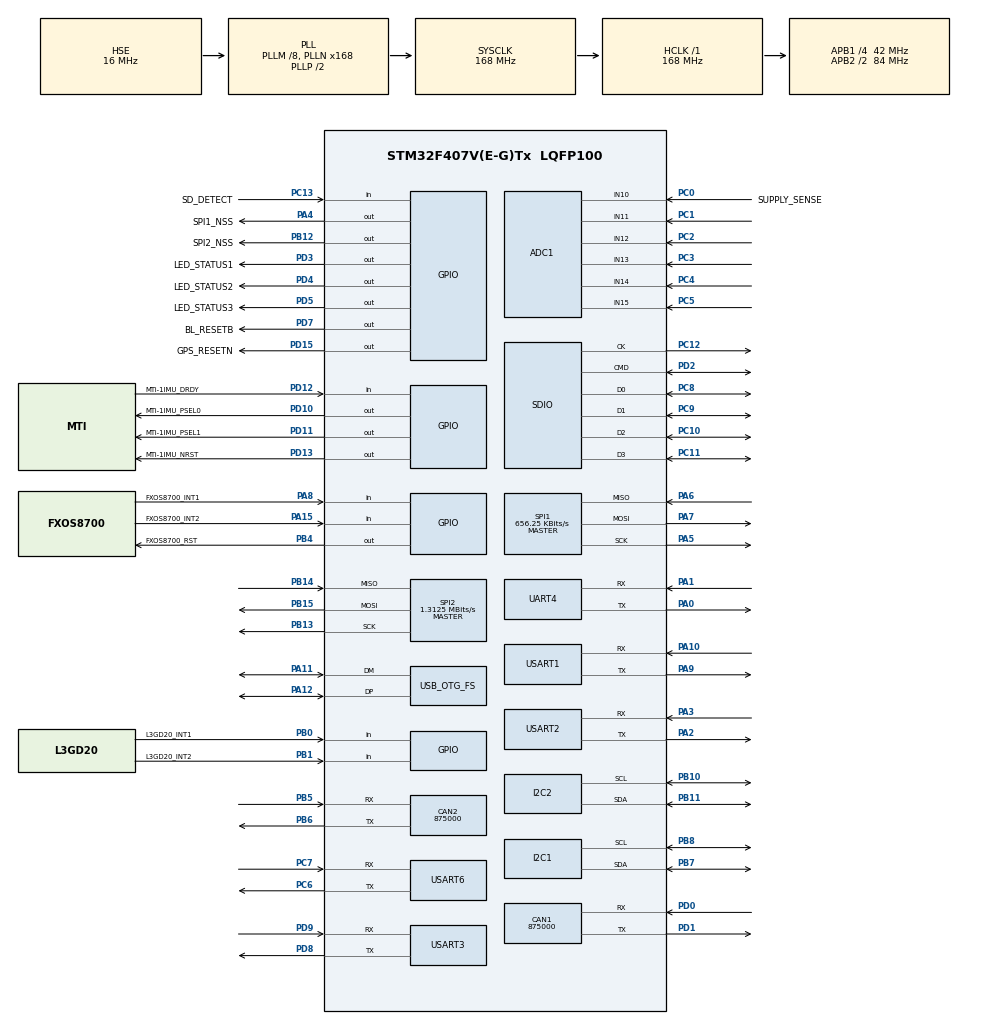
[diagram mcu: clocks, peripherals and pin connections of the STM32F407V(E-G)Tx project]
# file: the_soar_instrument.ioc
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ADC1.Channel-0\#ChannelRegularConversion=ADC_CHANNEL_10
ADC1.NbrOfConversionFlag=1
ADC1.Rank-0\#ChannelRegularConversion=1
ADC1.SamplingTime-0\#ChannelRegularConversion=ADC_SAMPLETIME_3CYCLES
ADC1.master=1
CAN1.CalculateBaudRate=875000
CAN1.CalculateTimeBit=1142.85
CAN1.CalculateTimeQuantum=380.95238095238096
CAN2.CalculateBaudRate=875000
CAN2.CalculateTimeBit=1142.85
CAN2.CalculateTimeQuantum=380.95238095238096
Dma.Request0=SDIO_RX
Dma.Request1=SDIO_TX
Dma.Request2=SPI2_RX
Dma.Request3=SPI2_TX
Dma.Request4=SPI1_RX
Dma.Request5=SPI1_TX
Dma.SDIO_RX.0.Direction=DMA_PERIPH_TO_MEMORY
Dma.SDIO_RX.0.FIFOMode=DMA_FIFOMODE_ENABLE
Dma.SDIO_RX.0.FIFOThreshold=DMA_FIFO_THRESHOLD_FULL
Dma.SDIO_RX.0.Instance=DMA2_Stream3
Dma.SDIO_RX.0.MemBurst=DMA_MBURST_INC4
Dma.SDIO_RX.0.MemDataAlignment=DMA_MDATAALIGN_WORD
Dma.SDIO_RX.0.MemInc=DMA_MINC_ENABLE
Dma.SDIO_RX.0.Mode=DMA_PFCTRL
Dma.SDIO_RX.0.PeriphBurst=DMA_PBURST_INC4
Dma.SDIO_RX.0.PeriphDataAlignment=DMA_PDATAALIGN_WORD
Dma.SDIO_RX.0.PeriphInc=DMA_PINC_DISABLE
Dma.SDIO_RX.0.Priority=DMA_PRIORITY_LOW
Dma.SDIO_TX.1.Direction=DMA_MEMORY_TO_PERIPH
Dma.SDIO_TX.1.FIFOMode=DMA_FIFOMODE_ENABLE
Dma.SDIO_TX.1.FIFOThreshold=DMA_FIFO_THRESHOLD_FULL
Dma.SDIO_TX.1.Instance=DMA2_Stream6
Dma.SDIO_TX.1.MemBurst=DMA_MBURST_INC4
Dma.SDIO_TX.1.MemDataAlignment=DMA_MDATAALIGN_WORD
Dma.SDIO_TX.1.MemInc=DMA_MINC_ENABLE
Dma.SDIO_TX.1.Mode=DMA_PFCTRL
Dma.SDIO_TX.1.PeriphBurst=DMA_PBURST_INC4
Dma.SDIO_TX.1.PeriphDataAlignment=DMA_PDATAALIGN_WORD
Dma.SDIO_TX.1.PeriphInc=DMA_PINC_DISABLE
Dma.SDIO_TX.1.Priority=DMA_PRIORITY_LOW
Dma.SPI1_RX.4.Direction=DMA_PERIPH_TO_MEMORY
Dma.SPI1_RX.4.FIFOMode=DMA_FIFOMODE_DISABLE
Dma.SPI1_RX.4.Instance=DMA2_Stream0
Dma.SPI1_RX.4.MemDataAlignment=DMA_MDATAALIGN_BYTE
Dma.SPI1_RX.4.MemInc=DMA_MINC_ENABLE
Dma.SPI1_RX.4.Mode=DMA_NORMAL
Dma.SPI1_RX.4.PeriphDataAlignment=DMA_PDATAALIGN_BYTE
Dma.SPI1_RX.4.PeriphInc=DMA_PINC_DISABLE
Dma.SPI1_RX.4.Priority=DMA_PRIORITY_LOW
Dma.SPI1_TX.5.Direction=DMA_MEMORY_TO_PERIPH
Dma.SPI1_TX.5.FIFOMode=DMA_FIFOMODE_DISABLE
Dma.SPI1_TX.5.Instance=DMA2_Stream5
Dma.SPI1_TX.5.MemDataAlignment=DMA_MDATAALIGN_BYTE
Dma.SPI1_TX.5.MemInc=DMA_MINC_ENABLE
Dma.SPI1_TX.5.Mode=DMA_NORMAL
Dma.SPI1_TX.5.PeriphDataAlignment=DMA_PDATAALIGN_BYTE
Dma.SPI1_TX.5.PeriphInc=DMA_PINC_DISABLE
Dma.SPI1_TX.5.Priority=DMA_PRIORITY_LOW
Dma.SPI2_RX.2.Direction=DMA_PERIPH_TO_MEMORY
Dma.SPI2_RX.2.FIFOMode=DMA_FIFOMODE_DISABLE
Dma.SPI2_RX.2.Instance=DMA1_Stream3
Dma.SPI2_RX.2.MemDataAlignment=DMA_MDATAALIGN_BYTE
Dma.SPI2_RX.2.MemInc=DMA_MINC_ENABLE
Dma.SPI2_RX.2.Mode=DMA_NORMAL
Dma.SPI2_RX.2.PeriphDataAlignment=DMA_PDATAALIGN_BYTE
Dma.SPI2_RX.2.PeriphInc=DMA_PINC_DISABLE
Dma.SPI2_RX.2.Priority=DMA_PRIORITY_LOW
Dma.SPI2_TX.3.Direction=DMA_MEMORY_TO_PERIPH
Dma.SPI2_TX.3.FIFOMode=DMA_FIFOMODE_DISABLE
Dma.SPI2_TX.3.Instance=DMA1_Stream4
Dma.SPI2_TX.3.MemDataAlignment=DMA_MDATAALIGN_BYTE
Dma.SPI2_TX.3.MemInc=DMA_MINC_ENABLE
Dma.SPI2_TX.3.Mode=DMA_NORMAL
Dma.SPI2_TX.3.PeriphDataAlignment=DMA_PDATAALIGN_BYTE
Dma.SPI2_TX.3.PeriphInc=DMA_PINC_DISABLE
Dma.SPI2_TX.3.Priority=DMA_PRIORITY_LOW
FATFS.BSP.number=1
FATFS0.BSP.STBoard=false
FATFS0.BSP.api=Unknown
FATFS0.BSP.i2caddr=0
FATFS0.BSP.instance=PC13-ANTI_TAMP
FATFS0.BSP.ip=GPIO
FATFS0.BSP.mode=Input
FATFS0.BSP.name=Detect_SDIO
FATFS0.BSP.solution=PC13-ANTI_TAMP
FREERTOS.INCLUDE_vTaskDelayUntil=1
FREERTOS.Tasks01=defaultTask,0,512,StartDefaultTask,Default,NULL,Dynamic,NULL,NULL
I2C1.I2C_Mode=I2C_Fast
I2C2.I2C_Mode=I2C_Fast
Mcu.Family=STM32F4
Mcu.Name=STM32F407V(E-G)Tx
Mcu.Package=LQFP100
NVIC.DMA1_Stream3_IRQn=true\:5\:0\:false\:false\:true\:true\:false\:true
NVIC.DMA1_Stream4_IRQn=true\:5\:0\:false\:false\:true\:true\:false\:true
NVIC.DMA2_Stream0_IRQn=true\:5\:0\:false\:false\:true\:true\:false\:true
NVIC.DMA2_Stream3_IRQn=true\:6\:0\:true\:false\:true\:true\:false\:true
NVIC.DMA2_Stream5_IRQn=true\:5\:0\:false\:false\:true\:true\:false\:true
NVIC.DMA2_Stream6_IRQn=true\:6\:0\:true\:false\:true\:true\:false\:true
NVIC.I2C1_ER_IRQn=true\:5\:0\:false\:false\:true\:true\:true\:true
NVIC.I2C1_EV_IRQn=true\:5\:0\:false\:false\:true\:true\:true\:true
NVIC.I2C2_ER_IRQn=true\:5\:0\:false\:false\:true\:true\:true\:true
NVIC.I2C2_EV_IRQn=true\:5\:0\:false\:false\:true\:true\:true\:true
NVIC.OTG_FS_IRQn=true\:5\:0\:false\:false\:true\:false\:false\:true
NVIC.PriorityGroup=NVIC_PRIORITYGROUP_4
NVIC.SDIO_IRQn=true\:7\:0\:true\:false\:true\:true\:true\:true
NVIC.TIM1_UP_TIM10_IRQn=true\:0\:0\:false\:false\:true\:false\:false\:true
NVIC.TimeBase=TIM1_UP_TIM10_IRQn
NVIC.TimeBaseIP=TIM1
PA0-WKUP.Mode=Asynchronous
PA0-WKUP.Signal=UART4_TX
PA1.Mode=Asynchronous
PA1.Signal=UART4_RX
PA10.Mode=Asynchronous
PA10.Signal=USART1_RX
PA11.Mode=Device_Only
PA11.Signal=USB_OTG_FS_DM
PA12.Mode=Device_Only
PA12.Signal=USB_OTG_FS_DP
PA13.Mode=Trace_Asynchronous_SW
PA13.Signal=SYS_JTMS-SWDIO
PA14.Mode=Trace_Asynchronous_SW
PA14.Signal=SYS_JTCK-SWCLK
PA15.GPIO_Label=FXOS8700_INT2
PA15.Signal=GPIO_Input
PA2.Mode=Asynchronous
PA2.Signal=USART2_TX
PA3.Mode=Asynchronous
PA3.Signal=USART2_RX
PA4.GPIO_Label=SPI1_NSS
PA4.GPIO_Speed=GPIO_SPEED_FREQ_VERY_HIGH
PA4.PinState=GPIO_PIN_SET
PA4.Signal=GPIO_Output
PA5.Mode=Full_Duplex_Master
PA5.Signal=SPI1_SCK
PA6.Mode=Full_Duplex_Master
PA6.Signal=SPI1_MISO
PA7.Mode=Full_Duplex_Master
PA7.Signal=SPI1_MOSI
PA8.GPIO_Label=FXOS8700_INT1
PA8.Signal=GPIO_Input
PA9.Mode=Asynchronous
PA9.Signal=USART1_TX
PB0.GPIO_Label=L3GD20_INT1
PB0.Signal=GPIO_Input
PB1.GPIO_Label=L3GD20_INT2
PB1.Signal=GPIO_Input
PB10.Mode=I2C
PB10.Signal=I2C2_SCL
PB11.Mode=I2C
PB11.Signal=I2C2_SDA
PB12.GPIO_Label=SPI2_NSS
PB12.GPIO_Speed=GPIO_SPEED_FREQ_VERY_HIGH
PB12.PinState=GPIO_PIN_SET
PB12.Signal=GPIO_Output
PB13.Mode=Full_Duplex_Master
PB13.Signal=SPI2_SCK
PB14.Mode=Full_Duplex_Master
PB14.Signal=SPI2_MISO
PB15.Mode=Full_Duplex_Master
PB15.Signal=SPI2_MOSI
PB3.Mode=Trace_Asynchronous_SW
PB3.Signal=SYS_JTDO-SWO
PB4.GPIO_Label=FXOS8700_RST
PB4.Signal=GPIO_Output
PB5.GPIO_PuPd=GPIO_PULLUP
PB5.Mode=CAN_Activate
PB5.Signal=CAN2_RX
PB6.GPIO_PuPd=GPIO_PULLUP
PB6.Mode=CAN_Activate
PB6.Signal=CAN2_TX
PB7.Mode=I2C
PB7.Signal=I2C1_SDA
PB8.Mode=I2C
PB8.Signal=I2C1_SCL
PC0.GPIO_Label=SUPPLY_SENSE
PC0.Signal=ADCx_IN10
PC1.Signal=ADCx_IN11
PC10.GPIO_PuPd=GPIO_PULLUP
PC10.GPIO_Speed_High_Default=GPIO_SPEED_FREQ_HIGH
PC10.Mode=SD_4_bits_Wide_bus
PC10.Signal=SDIO_D2
PC11.GPIO_PuPd=GPIO_PULLUP
PC11.GPIO_Speed_High_Default=GPIO_SPEED_FREQ_HIGH
PC11.Mode=SD_4_bits_Wide_bus
PC11.Signal=SDIO_D3
PC12.GPIO_Speed_High_Default=GPIO_SPEED_FREQ_HIGH
PC12.Mode=SD_4_bits_Wide_bus
PC12.Signal=SDIO_CK
PC13-ANTI_TAMP.GPIO_Label=SD_DETECT
PC13-ANTI_TAMP.GPIO_PuPd=GPIO_PULLDOWN
PC13-ANTI_TAMP.Signal=GPIO_Input
PC2.Signal=ADCx_IN12
PC3.Signal=ADCx_IN13
PC4.Signal=ADCx_IN14
PC5.Signal=ADCx_IN15
PC6.Mode=Asynchronous
PC6.Signal=USART6_TX
PC7.Mode=Asynchronous
PC7.Signal=USART6_RX
PC8.GPIO_PuPd=GPIO_PULLUP
PC8.GPIO_Speed_High_Default=GPIO_SPEED_FREQ_HIGH
PC8.Mode=SD_4_bits_Wide_bus
PC8.Signal=SDIO_D0
PC9.GPIO_PuPd=GPIO_PULLUP
PC9.GPIO_Speed_High_Default=GPIO_SPEED_FREQ_HIGH
PC9.Mode=SD_4_bits_Wide_bus
PC9.Signal=SDIO_D1
PD0.Mode=CAN_Activate
PD0.Signal=CAN1_RX
PD1.Mode=CAN_Activate
PD1.Signal=CAN1_TX
PD10.GPIO_Label=MTi-1IMU_PSEL0
PD10.Signal=GPIO_Output
PD11.GPIO_Label=MTi-1IMU_PSEL1
PD11.Signal=GPIO_Output
PD12.GPIO_Label=MTi-1IMU_DRDY
PD12.Signal=GPIO_Input
PD13.GPIO_Label=MTi-1IMU_NRST
PD13.Signal=GPIO_Output
PD15.GPIO_Label=GPS_RESETN
PD15.Signal=GPIO_Output
PD2.GPIO_PuPd=GPIO_PULLUP
PD2.GPIO_Speed_High_Default=GPIO_SPEED_FREQ_HIGH
PD2.Mode=SD_4_bits_Wide_bus
PD2.Signal=SDIO_CMD
PD3.GPIO_Label=LED_STATUS1
PD3.Signal=GPIO_Output
PD4.GPIO_Label=LED_STATUS2
PD4.Signal=GPIO_Output
PD5.GPIO_Label=LED_STATUS3
PD5.Signal=GPIO_Output
PD7.GPIO_Label=BL_RESETB
PD7.Signal=GPIO_Output
PD8.Mode=Asynchronous
PD8.Signal=USART3_TX
PD9.Mode=Asynchronous
PD9.Signal=USART3_RX
PH0-OSC_IN.Mode=HSE-External-Oscillator
PH0-OSC_IN.Signal=RCC_OSC_IN
PH1-OSC_OUT.Mode=HSE-External-Oscillator
PH1-OSC_OUT.Signal=RCC_OSC_OUT
ProjectManager.HeapSize=0x200
ProjectManager.StackSize=0x400
ProjectManager.TargetToolchain=STM32CubeIDE
RCC.48MHZClocksFreq_Value=48000000
RCC.AHBFreq_Value=168000000
RCC.APB1CLKDivider=RCC_HCLK_DIV4
RCC.APB1Freq_Value=42000000
RCC.APB1TimFreq_Value=84000000
RCC.APB2CLKDivider=RCC_HCLK_DIV2
RCC.APB2Freq_Value=84000000
RCC.APB2TimFreq_Value=168000000
RCC.CortexFreq_Value=168000000
RCC.HCLKFreq_Value=168000000
RCC.HSE_VALUE=16000000
RCC.HSI_VALUE=16000000
RCC.LSE_VALUE=32768
RCC.PLLM=8
RCC.PLLN=168
RCC.PLLQ=7
RCC.SYSCLKFreq_VALUE=168000000
RCC.SYSCLKSource=RCC_SYSCLKSOURCE_PLLCLK
RCC.VCOOutputFreq_Value=336000000
SDIO.ClockDiv=4
SH.ADCx_IN10.0=ADC1_IN10,IN10
SH.ADCx_IN11.0=ADC1_IN11,IN11
SH.ADCx_IN12.0=ADC1_IN12,IN12
SH.ADCx_IN13.0=ADC1_IN13,IN13
SH.ADCx_IN14.0=ADC1_IN14,IN14
SH.ADCx_IN15.0=ADC1_IN15,IN15
SPI1.BaudRatePrescaler=SPI_BAUDRATEPRESCALER_128
SPI1.CLKPhase=SPI_PHASE_2EDGE
SPI1.CLKPolarity=SPI_POLARITY_HIGH
SPI1.CalculateBaudRate=656.25 KBits/s
SPI1.Direction=SPI_DIRECTION_2LINES
SPI1.Mode=SPI_MODE_MASTER
SPI1.VirtualType=VM_MASTER
SPI2.BaudRatePrescaler=SPI_BAUDRATEPRESCALER_32
SPI2.CalculateBaudRate=1.3125 MBits/s
SPI2.Direction=SPI_DIRECTION_2LINES
SPI2.Mode=SPI_MODE_MASTER
SPI2.VirtualType=VM_MASTER
UART4.VirtualMode=Asynchronous
USART1.VirtualMode=VM_ASYNC
USART2.VirtualMode=VM_ASYNC
USART3.VirtualMode=VM_ASYNC
USART6.VirtualMode=VM_ASYNC
USB_DEVICE.CLASS_NAME_FS=CDC
USB_DEVICE.VirtualMode-CDC_FS=Cdc
USB_DEVICE.VirtualModeFS=Cdc_FS
USB_OTG_FS.VirtualMode=Device_Only
VP_FATFS_VS_SDIO.Mode=SDIO
VP_FREERTOS_VS_CMSIS_V1.Mode=CMSIS_V1
VP_SYS_VS_tim1.Mode=TIM1
VP_USB_DEVICE_VS_USB_DEVICE_CDC_FS.Mode=CDC_FS
board=custom

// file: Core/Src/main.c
/* USER CODE BEGIN Header */
/**
  ******************************************************************************
  * @file           : main.c
  * @brief          : Main program body
  ******************************************************************************
  * @attention
  *
  * <h2><center>&copy; Copyright (c) 2020 STMicroelectronics.
  * All rights reserved.</center></h2>
  *
  * This software component is licensed by ST under Ultimate Liberty license
  * SLA0044, the "License"; You may not use this file except in compliance with
  * the License. You may obtain a copy of the License at:
  *                             www.st.com/SLA0044
  *
  ******************************************************************************
  */
/* USER CODE END Header */
#include "main.h"
#include "cmsis_os.h"
#include "fatfs.h"
#include "usb_device.h"

/* USER CODE BEGIN Includes */
#include "FreeRTOS.h"
#include "my_assert.h"
/* USER CODE END Includes */

ADC_HandleTypeDef hadc1;

CAN_HandleTypeDef hcan1;
CAN_HandleTypeDef hcan2;

I2C_HandleTypeDef hi2c1;
I2C_HandleTypeDef hi2c2;

SD_HandleTypeDef hsd;
DMA_HandleTypeDef hdma_sdio_rx;
DMA_HandleTypeDef hdma_sdio_tx;

SPI_HandleTypeDef hspi1;
SPI_HandleTypeDef hspi2;
DMA_HandleTypeDef hdma_spi1_rx;
DMA_HandleTypeDef hdma_spi1_tx;
DMA_HandleTypeDef hdma_spi2_rx;
DMA_HandleTypeDef hdma_spi2_tx;

UART_HandleTypeDef huart4;
UART_HandleTypeDef huart1;
UART_HandleTypeDef huart2;
UART_HandleTypeDef huart3;
UART_HandleTypeDef huart6;

osThreadId defaultTaskHandle;
/* USER CODE BEGIN PV */
osThreadId testTaskHandle;
/* USER CODE END PV */

void SystemClock_Config(void);
static void MX_GPIO_Init(void);
static void MX_DMA_Init(void);
static void MX_CAN1_Init(void);
static void MX_I2C1_Init(void);
static void MX_I2C2_Init(void);
static void MX_SDIO_SD_Init(void);
static void MX_SPI1_Init(void);
static void MX_SPI2_Init(void);
static void MX_UART4_Init(void);
static void MX_USART1_UART_Init(void);
static void MX_USART2_UART_Init(void);
static void MX_USART6_UART_Init(void);
static void MX_ADC1_Init(void);
static void MX_USART3_UART_Init(void);
static void MX_CAN2_Init(void);
void StartDefaultTask(void const * argument);

/* USER CODE BEGIN PFP */
void StartTestTask(void const * argument);
/* USER CODE END PFP */

int main(void)
{
  /* USER CODE BEGIN 1 */
	SystemCoreClockUpdate();
	SystemCoreClock = 168000000; // dirty patch but works well :-)

#if configUSE_TRACE_FACILITY == 1
	vTraceEnable(TRC_START);
#endif
  /* USER CODE END 1 */

  /* MCU Configuration--------------------------------------------------------*/

  /* Reset of all peripherals, Initializes the Flash interface and the Systick. */
  HAL_Init();

  /* Configure the system clock */
  SystemClock_Config();

  /* Initialize all configured peripherals */
  MX_GPIO_Init();
  MX_DMA_Init();
  MX_CAN1_Init();
  MX_I2C1_Init();
  MX_I2C2_Init();
  MX_SDIO_SD_Init();
  MX_SPI1_Init();
  MX_SPI2_Init();
  MX_UART4_Init();
  MX_USART1_UART_Init();
  MX_USART2_UART_Init();
  MX_USART6_UART_Init();
  MX_FATFS_Init();
  MX_ADC1_Init();
  MX_USART3_UART_Init();
  MX_CAN2_Init();

  /* Create the thread(s) */
  /* definition and creation of defaultTask */
  osThreadDef(defaultTask, StartDefaultTask, osPriorityNormal, 0, 512);
  defaultTaskHandle = osThreadCreate(osThread(defaultTask), NULL);

  /* USER CODE BEGIN RTOS_THREADS */
  /* add threads, ... */
  osThreadDef(testTask, StartTestTask, osPriorityNormal, 0, 512);
  testTaskHandle = osThreadCreate(osThread(testTask), NULL);
  /* USER CODE END RTOS_THREADS */

  /* Start scheduler */
  osKernelStart();

  /* We should never get here as control is now taken by the scheduler */
  /* Infinite loop */
  while (1)
  {

  }
}

void SystemClock_Config(void)
{
  RCC_OscInitTypeDef RCC_OscInitStruct = {0};
  RCC_ClkInitTypeDef RCC_ClkInitStruct = {0};

  /** Configure the main internal regulator output voltage
  */
  __HAL_RCC_PWR_CLK_ENABLE();
  __HAL_PWR_VOLTAGESCALING_CONFIG(PWR_REGULATOR_VOLTAGE_SCALE1);
  /** Initializes the RCC Oscillators according to the specified parameters
  * in the RCC_OscInitTypeDef structure.
  */
  RCC_OscInitStruct.OscillatorType = RCC_OSCILLATORTYPE_HSE;
  RCC_OscInitStruct.HSEState = RCC_HSE_ON;
  RCC_OscInitStruct.PLL.PLLState = RCC_PLL_ON;
  RCC_OscInitStruct.PLL.PLLSource = RCC_PLLSOURCE_HSE;
  RCC_OscInitStruct.PLL.PLLM = 8;
  RCC_OscInitStruct.PLL.PLLN = 168;
  RCC_OscInitStruct.PLL.PLLP = RCC_PLLP_DIV2;
  RCC_OscInitStruct.PLL.PLLQ = 7;
  if (HAL_RCC_OscConfig(&RCC_OscInitStruct) != HAL_OK)
  {
    Error_Handler();
  }
  /** Initializes the CPU, AHB and APB buses clocks
  */
  RCC_ClkInitStruct.ClockType = RCC_CLOCKTYPE_HCLK|RCC_CLOCKTYPE_SYSCLK
                              |RCC_CLOCKTYPE_PCLK1|RCC_CLOCKTYPE_PCLK2;
  RCC_ClkInitStruct.SYSCLKSource = RCC_SYSCLKSOURCE_PLLCLK;
  RCC_ClkInitStruct.AHBCLKDivider = RCC_SYSCLK_DIV1;
  RCC_ClkInitStruct.APB1CLKDivider = RCC_HCLK_DIV4;
  RCC_ClkInitStruct.APB2CLKDivider = RCC_HCLK_DIV2;

  if (HAL_RCC_ClockConfig(&RCC_ClkInitStruct, FLASH_LATENCY_5) != HAL_OK)
  {
    Error_Handler();
  }
}

static void MX_ADC1_Init(void)
{

  ADC_ChannelConfTypeDef sConfig = {0};

  /** Configure the global features of the ADC (Clock, Resolution, Data Alignment and number of conversion)
  */
  hadc1.Instance = ADC1;
  hadc1.Init.ClockPrescaler = ADC_CLOCK_SYNC_PCLK_DIV4;
  hadc1.Init.Resolution = ADC_RESOLUTION_12B;
  hadc1.Init.ScanConvMode = DISABLE;
  hadc1.Init.ContinuousConvMode = DISABLE;
  hadc1.Init.DiscontinuousConvMode = DISABLE;
  hadc1.Init.ExternalTrigConvEdge = ADC_EXTERNALTRIGCONVEDGE_NONE;
  hadc1.Init.ExternalTrigConv = ADC_SOFTWARE_START;
  hadc1.Init.DataAlign = ADC_DATAALIGN_RIGHT;
  hadc1.Init.NbrOfConversion = 1;
  hadc1.Init.DMAContinuousRequests = DISABLE;
  hadc1.Init.EOCSelection = ADC_EOC_SINGLE_CONV;
  if (HAL_ADC_Init(&hadc1) != HAL_OK)
  {
    Error_Handler();
  }
  /** Configure for the selected ADC regular channel its corresponding rank in the sequencer and its sample time.
  */
  sConfig.Channel = ADC_CHANNEL_10;
  sConfig.Rank = 1;
  sConfig.SamplingTime = ADC_SAMPLETIME_3CYCLES;
  if (HAL_ADC_ConfigChannel(&hadc1, &sConfig) != HAL_OK)
  {
    Error_Handler();
  }

}

static void MX_CAN1_Init(void)
{

  hcan1.Instance = CAN1;
  hcan1.Init.Prescaler = 16;
  hcan1.Init.Mode = CAN_MODE_NORMAL;
  hcan1.Init.SyncJumpWidth = CAN_SJW_1TQ;
  hcan1.Init.TimeSeg1 = CAN_BS1_1TQ;
  hcan1.Init.TimeSeg2 = CAN_BS2_1TQ;
  hcan1.Init.TimeTriggeredMode = DISABLE;
  hcan1.Init.AutoBusOff = DISABLE;
  hcan1.Init.AutoWakeUp = DISABLE;
  hcan1.Init.AutoRetransmission = DISABLE;
  hcan1.Init.ReceiveFifoLocked = DISABLE;
  hcan1.Init.TransmitFifoPriority = DISABLE;
  if (HAL_CAN_Init(&hcan1) != HAL_OK)
  {
    Error_Handler();
  }

}

static void MX_CAN2_Init(void)
{

  hcan2.Instance = CAN2;
  hcan2.Init.Prescaler = 16;
  hcan2.Init.Mode = CAN_MODE_NORMAL;
  hcan2.Init.SyncJumpWidth = CAN_SJW_1TQ;
  hcan2.Init.TimeSeg1 = CAN_BS1_1TQ;
  hcan2.Init.TimeSeg2 = CAN_BS2_1TQ;
  hcan2.Init.TimeTriggeredMode = DISABLE;
  hcan2.Init.AutoBusOff = DISABLE;
  hcan2.Init.AutoWakeUp = DISABLE;
  hcan2.Init.AutoRetransmission = DISABLE;
  hcan2.Init.ReceiveFifoLocked = DISABLE;
  hcan2.Init.TransmitFifoPriority = DISABLE;
  if (HAL_CAN_Init(&hcan2) != HAL_OK)
  {
    Error_Handler();
  }

}

static void MX_I2C1_Init(void)
{

  hi2c1.Instance = I2C1;
  hi2c1.Init.ClockSpeed = 400000;
  hi2c1.Init.DutyCycle = I2C_DUTYCYCLE_2;
  hi2c1.Init.OwnAddress1 = 0;
  hi2c1.Init.AddressingMode = I2C_ADDRESSINGMODE_7BIT;
  hi2c1.Init.DualAddressMode = I2C_DUALADDRESS_DISABLE;
  hi2c1.Init.OwnAddress2 = 0;
  hi2c1.Init.GeneralCallMode = I2C_GENERALCALL_DISABLE;
  hi2c1.Init.NoStretchMode = I2C_NOSTRETCH_DISABLE;
  if (HAL_I2C_Init(&hi2c1) != HAL_OK)
  {
    Error_Handler();
  }

}

static void MX_I2C2_Init(void)
{

  hi2c2.Instance = I2C2;
  hi2c2.Init.ClockSpeed = 400000;
  hi2c2.Init.DutyCycle = I2C_DUTYCYCLE_2;
  hi2c2.Init.OwnAddress1 = 0;
  hi2c2.Init.AddressingMode = I2C_ADDRESSINGMODE_7BIT;
  hi2c2.Init.DualAddressMode = I2C_DUALADDRESS_DISABLE;
  hi2c2.Init.OwnAddress2 = 0;
  hi2c2.Init.GeneralCallMode = I2C_GENERALCALL_DISABLE;
  hi2c2.Init.NoStretchMode = I2C_NOSTRETCH_DISABLE;
  if (HAL_I2C_Init(&hi2c2) != HAL_OK)
  {
    Error_Handler();
  }

}

static void MX_SDIO_SD_Init(void)
{

  hsd.Instance = SDIO;
  hsd.Init.ClockEdge = SDIO_CLOCK_EDGE_RISING;
  hsd.Init.ClockBypass = SDIO_CLOCK_BYPASS_DISABLE;
  hsd.Init.ClockPowerSave = SDIO_CLOCK_POWER_SAVE_DISABLE;
  hsd.Init.BusWide = SDIO_BUS_WIDE_1B;
  hsd.Init.HardwareFlowControl = SDIO_HARDWARE_FLOW_CONTROL_DISABLE;
  hsd.Init.ClockDiv = 4;

}

static void MX_SPI1_Init(void)
{

  /* SPI1 parameter configuration*/
  hspi1.Instance = SPI1;
  hspi1.Init.Mode = SPI_MODE_MASTER;
  hspi1.Init.Direction = SPI_DIRECTION_2LINES;
  hspi1.Init.DataSize = SPI_DATASIZE_8BIT;
  hspi1.Init.CLKPolarity = SPI_POLARITY_HIGH;
  hspi1.Init.CLKPhase = SPI_PHASE_2EDGE;
  hspi1.Init.NSS = SPI_NSS_SOFT;
  hspi1.Init.BaudRatePrescaler = SPI_BAUDRATEPRESCALER_128;
  hspi1.Init.FirstBit = SPI_FIRSTBIT_MSB;
  hspi1.Init.TIMode = SPI_TIMODE_DISABLE;
  hspi1.Init.CRCCalculation = SPI_CRCCALCULATION_DISABLE;
  hspi1.Init.CRCPolynomial = 10;
  if (HAL_SPI_Init(&hspi1) != HAL_OK)
  {
    Error_Handler();
  }

}

static void MX_SPI2_Init(void)
{

  /* SPI2 parameter configuration*/
  hspi2.Instance = SPI2;
  hspi2.Init.Mode = SPI_MODE_MASTER;
  hspi2.Init.Direction = SPI_DIRECTION_2LINES;
  hspi2.Init.DataSize = SPI_DATASIZE_8BIT;
  hspi2.Init.CLKPolarity = SPI_POLARITY_LOW;
  hspi2.Init.CLKPhase = SPI_PHASE_1EDGE;
  hspi2.Init.NSS = SPI_NSS_SOFT;
  hspi2.Init.BaudRatePrescaler = SPI_BAUDRATEPRESCALER_32;
  hspi2.Init.FirstBit = SPI_FIRSTBIT_MSB;
  hspi2.Init.TIMode = SPI_TIMODE_DISABLE;
  hspi2.Init.CRCCalculation = SPI_CRCCALCULATION_DISABLE;
  hspi2.Init.CRCPolynomial = 10;
  if (HAL_SPI_Init(&hspi2) != HAL_OK)
  {
    Error_Handler();
  }

}

static void MX_UART4_Init(void)
{

  huart4.Instance = UART4;
  huart4.Init.BaudRate = 115200;
  huart4.Init.WordLength = UART_WORDLENGTH_8B;
  huart4.Init.StopBits = UART_STOPBITS_1;
  huart4.Init.Parity = UART_PARITY_NONE;
  huart4.Init.Mode = UART_MODE_TX_RX;
  huart4.Init.HwFlowCtl = UART_HWCONTROL_NONE;
  huart4.Init.OverSampling = UART_OVERSAMPLING_16;
  if (HAL_UART_Init(&huart4) != HAL_OK)
  {
    Error_Handler();
  }

}

static void MX_USART1_UART_Init(void)
{

  huart1.Instance = USART1;
  huart1.Init.BaudRate = 115200;
  huart1.Init.WordLength = UART_WORDLENGTH_8B;
  huart1.Init.StopBits = UART_STOPBITS_1;
  huart1.Init.Parity = UART_PARITY_NONE;
  huart1.Init.Mode = UART_MODE_TX_RX;
  huart1.Init.HwFlowCtl = UART_HWCONTROL_NONE;
  huart1.Init.OverSampling = UART_OVERSAMPLING_16;
  if (HAL_UART_Init(&huart1) != HAL_OK)
  {
    Error_Handler();
  }

}

static void MX_USART2_UART_Init(void)
{

  huart2.Instance = USART2;
  huart2.Init.BaudRate = 115200;
  huart2.Init.WordLength = UART_WORDLENGTH_8B;
  huart2.Init.StopBits = UART_STOPBITS_1;
  huart2.Init.Parity = UART_PARITY_NONE;
  huart2.Init.Mode = UART_MODE_TX_RX;
  huart2.Init.HwFlowCtl = UART_HWCONTROL_NONE;
  huart2.Init.OverSampling = UART_OVERSAMPLING_16;
  if (HAL_UART_Init(&huart2) != HAL_OK)
  {
    Error_Handler();
  }

}

static void MX_USART3_UART_Init(void)
{

  huart3.Instance = USART3;
  huart3.Init.BaudRate = 115200;
  huart3.Init.WordLength = UART_WORDLENGTH_8B;
  huart3.Init.StopBits = UART_STOPBITS_1;
  huart3.Init.Parity = UART_PARITY_NONE;
  huart3.Init.Mode = UART_MODE_TX_RX;
  huart3.Init.HwFlowCtl = UART_HWCONTROL_NONE;
  huart3.Init.OverSampling = UART_OVERSAMPLING_16;
  if (HAL_UART_Init(&huart3) != HAL_OK)
  {
    Error_Handler();
  }

}

static void MX_USART6_UART_Init(void)
{

  huart6.Instance = USART6;
  huart6.Init.BaudRate = 115200;
  huart6.Init.WordLength = UART_WORDLENGTH_8B;
  huart6.Init.StopBits = UART_STOPBITS_1;
  huart6.Init.Parity = UART_PARITY_NONE;
  huart6.Init.Mode = UART_MODE_TX_RX;
  huart6.Init.HwFlowCtl = UART_HWCONTROL_NONE;
  huart6.Init.OverSampling = UART_OVERSAMPLING_16;
  if (HAL_UART_Init(&huart6) != HAL_OK)
  {
    Error_Handler();
  }

}

static void MX_DMA_Init(void)
{

  /* DMA controller clock enable */
  __HAL_RCC_DMA2_CLK_ENABLE();
  __HAL_RCC_DMA1_CLK_ENABLE();

  /* DMA interrupt init */
  /* DMA1_Stream3_IRQn interrupt configuration */
  HAL_NVIC_SetPriority(DMA1_Stream3_IRQn, 5, 0);
  HAL_NVIC_EnableIRQ(DMA1_Stream3_IRQn);
  /* DMA1_Stream4_IRQn interrupt configuration */
  HAL_NVIC_SetPriority(DMA1_Stream4_IRQn, 5, 0);
  HAL_NVIC_EnableIRQ(DMA1_Stream4_IRQn);
  /* DMA2_Stream0_IRQn interrupt configuration */
  HAL_NVIC_SetPriority(DMA2_Stream0_IRQn, 5, 0);
  HAL_NVIC_EnableIRQ(DMA2_Stream0_IRQn);
  /* DMA2_Stream3_IRQn interrupt configuration */
  HAL_NVIC_SetPriority(DMA2_Stream3_IRQn, 6, 0);
  HAL_NVIC_EnableIRQ(DMA2_Stream3_IRQn);
  /* DMA2_Stream5_IRQn interrupt configuration */
  HAL_NVIC_SetPriority(DMA2_Stream5_IRQn, 5, 0);
  HAL_NVIC_EnableIRQ(DMA2_Stream5_IRQn);
  /* DMA2_Stream6_IRQn interrupt configuration */
  HAL_NVIC_SetPriority(DMA2_Stream6_IRQn, 6, 0);
  HAL_NVIC_EnableIRQ(DMA2_Stream6_IRQn);

}

static void MX_GPIO_Init(void)
{
  GPIO_InitTypeDef GPIO_InitStruct = {0};

  /* GPIO Ports Clock Enable */
  __HAL_RCC_GPIOC_CLK_ENABLE();
  __HAL_RCC_GPIOH_CLK_ENABLE();
  __HAL_RCC_GPIOA_CLK_ENABLE();
  __HAL_RCC_GPIOB_CLK_ENABLE();
  __HAL_RCC_GPIOD_CLK_ENABLE();

  /*Configure GPIO pin Output Level */
  HAL_GPIO_WritePin(SPI1_NSS_GPIO_Port, SPI1_NSS_Pin, GPIO_PIN_SET);

  /*Configure GPIO pin Output Level */
  HAL_GPIO_WritePin(SPI2_NSS_GPIO_Port, SPI2_NSS_Pin, GPIO_PIN_SET);

  /*Configure GPIO pin Output Level */
  HAL_GPIO_WritePin(GPIOD, MTi_1IMU_PSEL0_Pin|MTi_1IMU_PSEL1_Pin|MTi_1IMU_NRST_Pin|GPS_RESETN_Pin
                          |LED_STATUS1_Pin|LED_STATUS2_Pin|LED_STATUS3_Pin|BL_RESETB_Pin, GPIO_PIN_RESET);

  /*Configure GPIO pin Output Level */
  HAL_GPIO_WritePin(FXOS8700_RST_GPIO_Port, FXOS8700_RST_Pin, GPIO_PIN_RESET);

  /*Configure GPIO pin : SD_DETECT_Pin */
  GPIO_InitStruct.Pin = SD_DETECT_Pin;
  GPIO_InitStruct.Mode = GPIO_MODE_INPUT;
  GPIO_InitStruct.Pull = GPIO_PULLDOWN;
  HAL_GPIO_Init(SD_DETECT_GPIO_Port, &GPIO_InitStruct);

  /*Configure GPIO pin : SPI1_NSS_Pin */
  GPIO_InitStruct.Pin = SPI1_NSS_Pin;
  GPIO_InitStruct.Mode = GPIO_MODE_OUTPUT_PP;
  GPIO_InitStruct.Pull = GPIO_NOPULL;
  GPIO_InitStruct.Speed = GPIO_SPEED_FREQ_VERY_HIGH;
  HAL_GPIO_Init(SPI1_NSS_GPIO_Port, &GPIO_InitStruct);

  /*Configure GPIO pins : L3GD20_INT1_Pin L3GD20_INT2_Pin */
  GPIO_InitStruct.Pin = L3GD20_INT1_Pin|L3GD20_INT2_Pin;
  GPIO_InitStruct.Mode = GPIO_MODE_INPUT;
  GPIO_InitStruct.Pull = GPIO_NOPULL;
  HAL_GPIO_Init(GPIOB, &GPIO_InitStruct);

  /*Configure GPIO pin : SPI2_NSS_Pin */
  GPIO_InitStruct.Pin = SPI2_NSS_Pin;
  GPIO_InitStruct.Mode = GPIO_MODE_OUTPUT_PP;
  GPIO_InitStruct.Pull = GPIO_NOPULL;
  GPIO_InitStruct.Speed = GPIO_SPEED_FREQ_VERY_HIGH;
  HAL_GPIO_Init(SPI2_NSS_GPIO_Port, &GPIO_InitStruct);

  /*Configure GPIO pins : MTi_1IMU_PSEL0_Pin MTi_1IMU_PSEL1_Pin MTi_1IMU_NRST_Pin GPS_RESETN_Pin
                           LED_STATUS1_Pin LED_STATUS2_Pin LED_STATUS3_Pin BL_RESETB_Pin */
  GPIO_InitStruct.Pin = MTi_1IMU_PSEL0_Pin|MTi_1IMU_PSEL1_Pin|MTi_1IMU_NRST_Pin|GPS_RESETN_Pin
                          |LED_STATUS1_Pin|LED_STATUS2_Pin|LED_STATUS3_Pin|BL_RESETB_Pin;
  GPIO_InitStruct.Mode = GPIO_MODE_OUTPUT_PP;
  GPIO_InitStruct.Pull = GPIO_NOPULL;
  GPIO_InitStruct.Speed = GPIO_SPEED_FREQ_LOW;
  HAL_GPIO_Init(GPIOD, &GPIO_InitStruct);

  /*Configure GPIO pin : MTi_1IMU_DRDY_Pin */
  GPIO_InitStruct.Pin = MTi_1IMU_DRDY_Pin;
  GPIO_InitStruct.Mode = GPIO_MODE_INPUT;
  GPIO_InitStruct.Pull = GPIO_NOPULL;
  HAL_GPIO_Init(MTi_1IMU_DRDY_GPIO_Port, &GPIO_InitStruct);

  /*Configure GPIO pins : FXOS8700_INT1_Pin FXOS8700_INT2_Pin */
  GPIO_InitStruct.Pin = FXOS8700_INT1_Pin|FXOS8700_INT2_Pin;
  GPIO_InitStruct.Mode = GPIO_MODE_INPUT;
  GPIO_InitStruct.Pull = GPIO_NOPULL;
  HAL_GPIO_Init(GPIOA, &GPIO_InitStruct);

  /*Configure GPIO pin : FXOS8700_RST_Pin */
  GPIO_InitStruct.Pin = FXOS8700_RST_Pin;
  GPIO_InitStruct.Mode = GPIO_MODE_OUTPUT_PP;
  GPIO_InitStruct.Pull = GPIO_NOPULL;
  GPIO_InitStruct.Speed = GPIO_SPEED_FREQ_LOW;
  HAL_GPIO_Init(FXOS8700_RST_GPIO_Port, &GPIO_InitStruct);

}

void StartDefaultTask(void const * argument)
{
  /* init code for USB_DEVICE */
  MX_USB_DEVICE_Init();
  /* USER CODE BEGIN 5 */

  /* Infinite loop */
  for(;;)
  {
    osDelay(portMAX_DELAY);  // Sleep forever
  }
  /* USER CODE END 5 */
}

 /**
  * @brief  Period elapsed callback in non blocking mode
  * @note   This function is called  when TIM1 interrupt took place, inside
  * HAL_TIM_IRQHandler(). It makes a direct call to HAL_IncTick() to increment
  * a global variable "uwTick" used as application time base.
  * @param  htim : TIM handle
  * @retval None
  */
void HAL_TIM_PeriodElapsedCallback(TIM_HandleTypeDef *htim)
{
  if (htim->Instance == TIM1) {
    HAL_IncTick();
  }
}

void Error_Handler(void)
{
  __disable_irq();
while (1)
  {
  }
}

/************************ (C) COPYRIGHT STMicroelectronics *****END OF FILE****/
